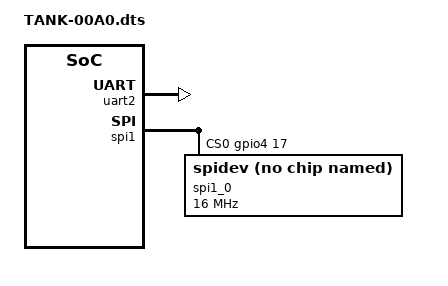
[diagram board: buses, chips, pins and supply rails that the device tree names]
/dts-v1/;
/plugin/;

/ {
	compatible = "ti,beaglebone", "ti,beaglebone-black";
	/* identification */
	part-number = "tank";
	/* version */
	version = "00A0";

	fragment@0 
	{
		target = <&am33xx_pinmux>;
		__overlay__ 
		{
			pinctrl_uart1: pinctrl_uart1_pins 
			{
				pinctrl-single,pins = <	0x180 0x30 	/* uart1_rx INPUT | PULLUP | MODE0 */
							0x184 0x00	/* uart1_tx MODE0 */
							>;
			};
		};	
	};
	fragment@1 
	{
		target = <&am33xx_pinmux>;
		__overlay__ 
		{
			pinctrl_spi1: pinctrl_spi1_pins 
			{
				pinctrl-single,pins = <	0x190 0x13    /* P9_31 = mcasp0_aclkx.spi1_sclk                 , OUTPUT_PULLUP | MODE3 */
							0x194 0x33    /* P9_29 = mcasp0_fsx.spi1_d0                     , INPUT_PULLUP  | MODE3 */
							0x198 0x13    /* P9_30 = mcasp0_axr0.spi1_d1                     , OUTPUT_PULLUP | MODE3 */
							0x19c 0x13    /* P9_28 = mcasp0_ahclkr.spi1_cs0                 , OUTPUT_PULLUP | MODE3 */                    

							/* BALLAST RELAY BOARD */

							0x090 0x07  	/* GPIO2_2 - K1 */
							0x094 0x07	/* GPIO2_3 - K2 */
							0x09C 0x07	/* GPIO2_5 - K3 */
							0x098 0x07	/* GPIO2_4 - K4 */
							0x024 0x07	/* GPIO0_23 - K5 */
							0x1A8 0x07	/* GPIO3_20 - K6 */
							0x164 0x37	/* GPIO0_7 - K6 (shares pin with 3_20) */
							0x190 0x07	/* GPIO2_6 - K7 */
							0x0C8 0x07	/* GPIO2_16 - K8 */
							0x030 0x07	/* GPIO1_12 - K9 */
							0x048 0x07	/* GPIO1_18 - K10 */
							0x034 0x07	/* GPIO1_13 - K11 */
							0x04C 0x07	/* GPIO1_19 - K12 */
							0x0AC 0x07	/* GPIO2_9 - J9 */
							0x014 0x07	/* GPIO1_5 - J8 */

							/* RELAY BOARD 1 */
	
							0x03C 0x07	/* GPIO1_15 - 1 */
							0x038 0x07	/* GPIO1_14 - 2 */
							0x02C 0x07	/* GPIO0_27 - 3 */
							0x07C 0x07	/* GPIO1_29 - 4 */
							0x0E0 0x07	/* GPIO2_22 - 5 */
							0x0E8 0x07	/* GPIO2_24 - 6 */
							0x0E4 0x07	/* GPIO2_23 - 7 */
							0x0EC 0x07	/* GPIO2_25 - 8 */

							/* RELAY BOARD 2 */

							0x0BC 0x07	/* GPIO2_13 - 1 */
							0x0B8 0x07	/* GPIO2_12 - 2 */
							0x0C8 0x07	/* GPIO2_16 - 3 */
							0x0C4 0x07	/* GPIO2_15 - 4 */
							0x0D0 0x07	/* GPIO0_8 - 5 */
							0x0DC 0x07	/* GPIO0_11 - 6 */
							0x0D4 0x07	/* GPIO0_9 - 7 */
							0x0CC 0x07	/* GPIO2_17 - 8 */
							>;
			};
		};
	};
	fragment@2
	{
		target = <&uart2>;
		__overlay__
		{
			status = "okay";
			pinctrl-names = "default";
			pinctrl-0 = <&pinctrl_uart1>;
		};
	};
	fragment@3
	{
		target = <&spi1>;
		__overlay__ 
		{
			#address-cells  = <1>;
			#size-cells     = <0>;
			status		= "okay";
			pinctrl-names   = "default";
			pinctrl-0       = <&pinctrl_spi1>;    
			cs-gpios        = <&gpio4 17 0>, <&gpio1 7 0>;
			spi1_0
			{
				#address-cells       	= <1>;
				#size-cells       	= <0>;
				compatible           	= "spidev";
				reg               	= <0>;
				spi-max-frequency	= <16000000>;
				spi-cpha;	   
			};
		};
	};
};
